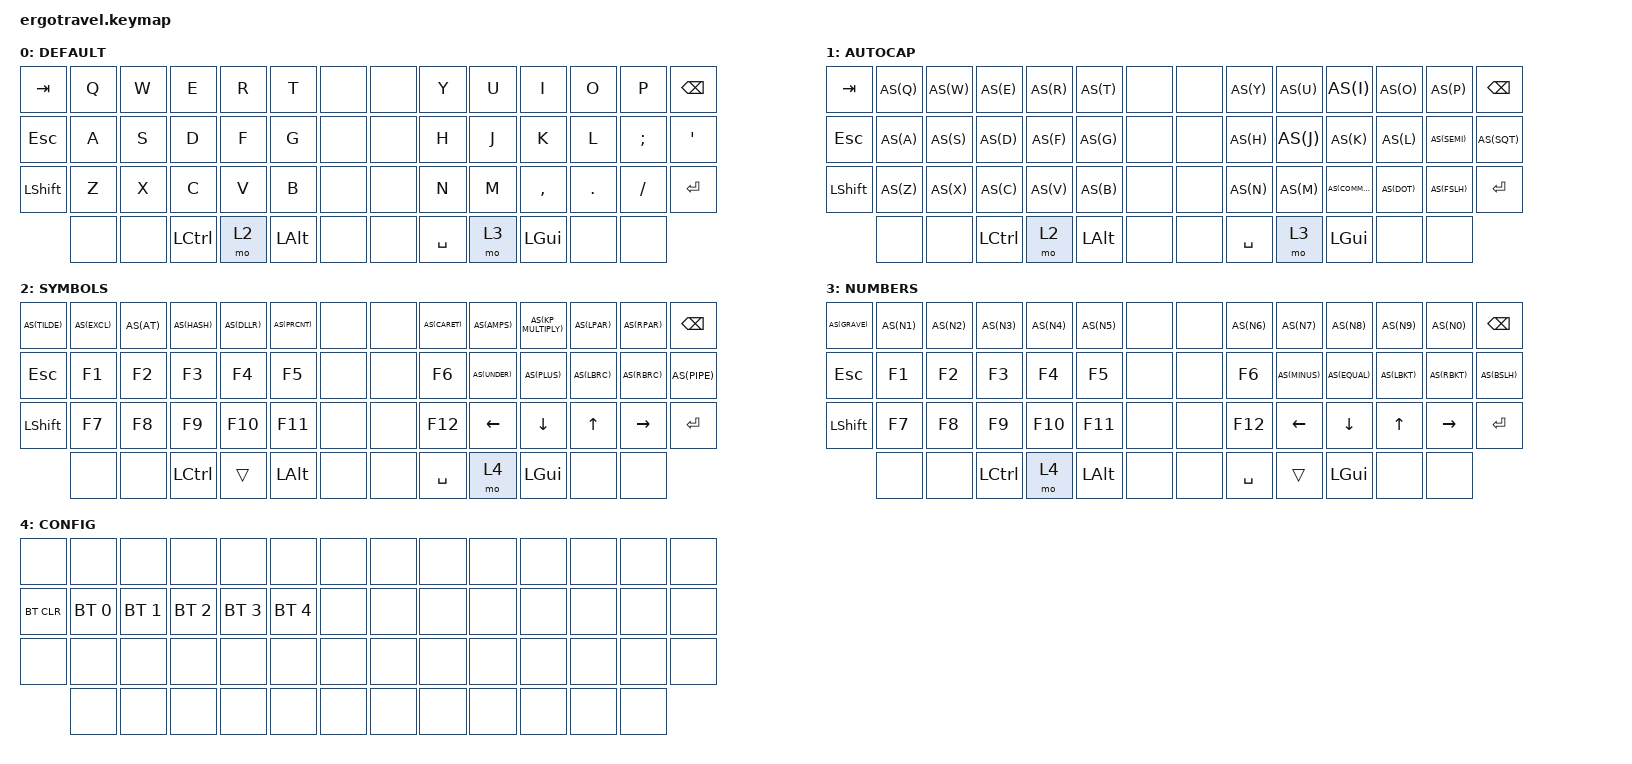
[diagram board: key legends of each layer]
/*
 * Copyright (c) 2020 The ZMK Contributors
 *
 * SPDX-License-Identifier: MIT
 */

#include <behaviors.dtsi>
#include <dt-bindings/zmk/keys.h>
#include <dt-bindings/zmk/bt.h>
#include <dt-bindings/zmk/ext_power.h>


//#define DEFAULT 0
#define DEFAULT 0
#define AUTOCAP 1
#define LOWER 2
#define RAISE 3
#define CONFIG 4
#define AS(keycode) &as LS(keycode) keycode

/ {
    combos {
        compatible = "zmk,combos";
        combo_esc {
            timeout-ms = <50>;
            key-positions = <3 4 5>;
            bindings = <&tog AUTOCAP>;
        };
    };
 };

/ {
        behaviors {
            as: auto_shift {
                compatible = "zmk,behavior-hold-tap";
                label = "AUTO_SHIFT";
                #binding-cells = <2>;
                tapping_term_ms = <140>;
                quick_tap_ms = <0>;
                flavor = "tap-preferred";
                bindings = <&kp>, <&kp>;
            };
        };

        keymap {
                compatible = "zmk,keymap";

                default_layer {
                        label = "DEFAULT";
// -------------------------------------------------------------------------------------------------------------------------------------------------------------------------------------------
// | TAB        | Q          | W          | E          | R          | T          |            |   |            | Y          | U          | I          | O          | P          | BKSP       |
// | ESC        | A          | S          | D          | F          | G          |            |   |            | H          | J          | K          | L          | ;          | '          |
// | SHFT       | Z          | X          | C          | V          | B          |            |   |            | N          | M          | ,          | .          | /          | RET        |
//              |            |            | CTRL       | LWR        | ALT        |            |   |            | SPC        | RSE        | GUI        |            |            |
                        bindings = <
     &kp TAB      &kp Q        &kp W        &kp E        &kp R        &kp T        &none            &none        &kp Y        &kp U        &kp I        &kp O        &kp P        &kp BSPC
     &kp ESC      &kp A        &kp S        &kp D        &kp F        &kp G        &none            &none        &kp H        &kp J        &kp K        &kp L        &kp SEMI     &kp SQT
     &kp LSHFT    &kp Z        &kp X        &kp C        &kp V        &kp B        &none            &none        &kp N        &kp M        &kp COMMA    &kp DOT      &kp FSLH     &kp RET
                  &none        &none        &kp LCTRL    &mo 2        &kp LALT     &none            &none        &kp SPACE    &mo 3        &kp LGUI     &none        &none
                        >;
                };

                autocap_layer {
                        label = "AUTOCAP";
// -------------------------------------------------------------------------------------------------------------------------------------------------------------------------------------------
// | TAB        | Q          | W          | E          | R          | T          |            |   |            | Y          | U          | I          | O          | P          | BKSP       |
// | ESC        | A          | S          | D          | F          | G          |            |   |            | H          | J          | K          | L          | ;          | '          |
// | SHFT       | Z          | X          | C          | V          | B          |            |   |            | N          | M          | ,          | .          | /          | RET        |
//              |            |            | CTRL       | LWR        | ALT        |            |   |            | SPC        | RSE        | GUI        |            |            |
                        bindings = <
     &kp TAB      AS(Q)        AS(W)        AS(E)        AS(R)        AS(T)        &none            &none        AS(Y)       AS(U)         AS(I)        AS(O)        AS(P)        &kp BSPC
     &kp ESC      AS(A)        AS(S)        AS(D)        AS(F)        AS(G)        &none            &none        AS(H)       AS(J)         AS(K)        AS(L)        AS(SEMI)     AS(SQT)
     &kp LSHFT    AS(Z)        AS(X)        AS(C)        AS(V)        AS(B)        &none            &none        AS(N)       AS(M)         AS(COMMA)    AS(DOT)      AS(FSLH)     &kp RET
                  &none        &none        &kp LCTRL    &mo 2        &kp LALT     &none            &none        &kp SPACE   &mo 3         &kp LGUI     &none        &none     
                        >;
                };

                lower_layer {
                        label = "SYMBOLS";
// -------------------------------------------------------------------------------------------------------------------------------------------------------------------------------------------
// | ~          | !          | @          | #          | $          | %          |            |   |            | ^          | &          | *          | (          | )          | BKSP       |
// | ESC        | F1         | F2         | F3         | F4         | F5         |            |   |            | F6         | _          | +          | {          | }          | |          |
// | SHFT       | F7         | F8         | F9         | F10        | F11        |            |   |            | F12        | LFT        | DWN        | UP         | RGT        | RET        |
//              |            |            | CTRL       |            | ALT        |            |   |            | SPC        |            | GUI        |            |            |
                        bindings = <

     AS(TILDE)    AS(EXCL)     AS(AT)       AS(HASH)     AS(DLLR)     AS(PRCNT)    &none            &none        AS(CARET)    AS(AMPS)     AS(KP_MULTIPLY)  AS(LPAR)    AS(RPAR)   &kp BSPC
     &kp ESC      &kp F1       &kp F2       &kp F3       &kp F4       &kp F5       &none            &none        &kp F6       AS(UNDER)    AS(PLUS)         AS(LBRC)    AS(RBRC)   AS(PIPE)
     &kp LSHFT    &kp F7       &kp F8       &kp F9       &kp F10      &kp F11      &none            &none        &kp F12      &kp LEFT     &kp DOWN         &kp UP      &kp RIGHT  &kp RET
                  &none        &none        &kp LCTRL    &trans       &kp LALT     &none            &none        &kp SPACE    &mo 4        &kp LGUI         &none       &none
                        >;
                };

                raise_layer {
                        label = "NUMBERS";
// -------------------------------------------------------------------------------------------------------------------------------------------------------------------------------------------
// | `          | 1          | 2          | 3          | 4          | 5          |            |   |            | 6          | 7          | 8          | 9          | 0          | BKSP       |
// | ESC        | F1         | F2         | F3         | F4         | F5         |            |   |            | F6         | -          | =          | [          | ]          | \          |
// | SHFT       | F7         | F8         | F9         | F10        | F11        |            |   |            | F12        | LFT        | DWN        | UP         | RGT        | RET        |
//              |            |            | CTRL       |            | ALT        |            |   |            | SPC        |            | GUI        |            |            |
                        bindings = <
     AS(GRAVE)    AS(N1)       AS(N2)       AS(N3)       AS(N4)       AS(N5)       &none            &none        AS(N6)       AS(N7)       AS(N8)       AS(N9)       AS(N0)       &kp BSPC
     &kp ESC      &kp F1       &kp F2       &kp F3       &kp F4       &kp F5       &none            &none        &kp F6       AS(MINUS)    AS(EQUAL)    AS(LBKT)     AS(RBKT)     AS(BSLH)
     &kp LSHFT    &kp F7       &kp F8       &kp F9       &kp F10      &kp F11      &none            &none        &kp F12      &kp LEFT     &kp DOWN     &kp UP       &kp RIGHT    &kp RET
                  &none        &none        &kp LCTRL    &mo 4        &kp LALT     &none            &none        &kp SPACE    &trans       &kp LGUI     &none        &none
                        >;
                };

                config_layer {
                        label = "CONFIG";
// -------------------------------------------------------------------------------------------------------------------------------------------------------------------------------------------
// |            |            |            |            |            |            |            |   |            |            |            |            |            |            |            |
// | BT_CLR     | BT_SEL 0   | BT_SEL 1   | BT_SEL 2   | BT_SEL 3   | BT_SEL 4   |            |   |            |            |            |            |            |            |            |
// |            |            |            |            |            |            |            |   |            |            |            |            |            |            |            |
//              |            |            |            |            |            |            |   |            |            |            |            |            |            |

                        bindings = <
     &none        &none        &none        &none        &none        &none        &none            &none        &none        &none        &none        &none        &none        &none 
     &bt BT_CLR   &bt BT_SEL 0 &bt BT_SEL 1 &bt BT_SEL 2 &bt BT_SEL 3 &bt BT_SEL 4 &none            &none        &none        &none        &none        &none        &none        &none
     &none        &none        &none        &none        &none        &none        &none            &none        &none        &none        &none        &none        &none        &none
                  &none        &none        &none        &none        &none        &none            &none        &none        &none        &none        &none        &none
                        >;
                };
        };
};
